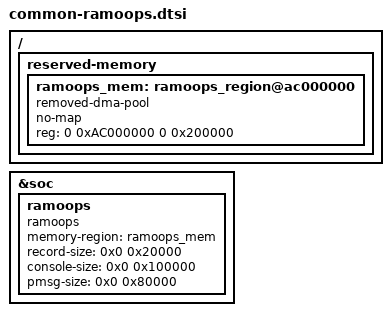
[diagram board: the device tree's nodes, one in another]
/ {
	reserved-memory {
		ramoops_mem: ramoops_region@ac000000 {
			compatible = "removed-dma-pool";
			no-map;
			reg = <0 0xAC000000 0 0x200000>;
		};
	};
};

&soc {
	ramoops {
		compatible = "ramoops";
		memory-region = <&ramoops_mem>;
		record-size = <0x0 0x20000>;
		console-size = <0x0 0x100000>;
		pmsg-size = <0x0 0x80000>;
	};
};
